AUTOSAR XML (schema 00044)
package /ComponentTypes
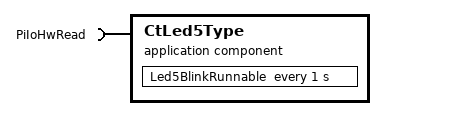
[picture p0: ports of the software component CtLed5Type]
  application sw component type CtLed5Type
    require port PiIoHwRead: client-com-spec=ReadChannel, required-interface=PiIoHwRead
    behavior CtLed5Type_InternalBehavior
      timing event TMT_Led5BlinkRunnable: start-on-event=Led5BlinkRunnable, period=1
      runnable Led5BlinkRunnable
        sync call SC_PiIoHwRead_ReadChannel: operation=PiIoHwRead.ReadChannel
  swc implementation CtLed5Type_Implementation: behavior=CtLed5Type_InternalBehavior
